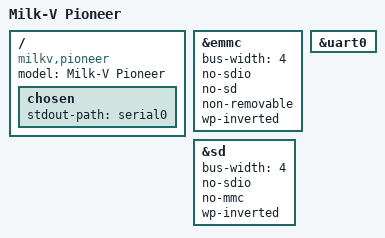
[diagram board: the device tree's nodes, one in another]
// SPDX-License-Identifier: GPL-2.0 OR MIT
/*
 * Copyright (C) 2022 Sophgo Technology Inc. All rights reserved.
 */

#include "sg2042.dtsi"

/ {
	model = "Milk-V Pioneer";
	compatible = "milkv,pioneer", "sophgo,sg2042";

	chosen {
		stdout-path = "serial0";
	};
};

&emmc {
	bus-width = <4>;
	no-sdio;
	no-sd;
	non-removable;
	wp-inverted;
	status = "okay";
};

&sd {
	bus-width = <4>;
	no-sdio;
	no-mmc;
	wp-inverted;
	status = "okay";
};

&uart0 {
	status = "okay";
};
